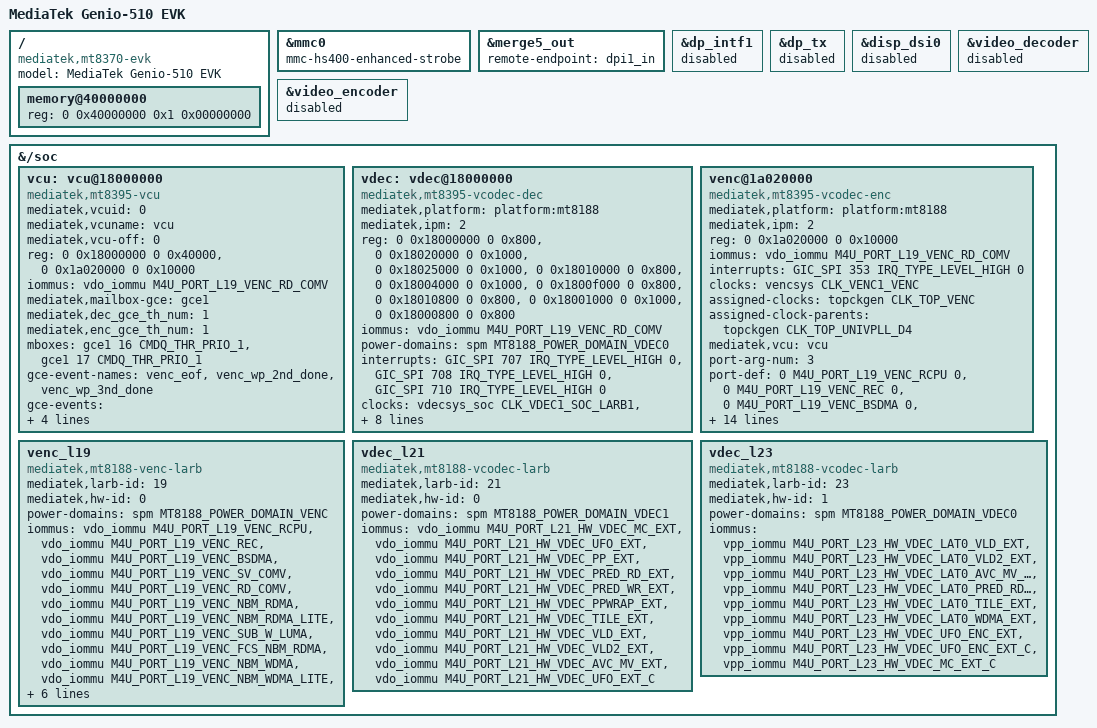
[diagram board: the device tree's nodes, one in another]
// SPDX-License-Identifier: (GPL-2.0 OR MIT)
/*
 * Copyright (c) 2025 Collabora Ltd.
 * Author: Louis-Alexis Eyraud <louisalexis.eyraud@collabora.com>
 */
/dts-v1/;

#include "mt8370.dtsi"
#include "mt8390-genio-common.dtsi"

/ {
	model = "MediaTek Genio-510 EVK";
	compatible = "mediatek,mt8370-evk", "mediatek,mt8370", "mediatek,mt8188";

	memory@40000000 {
		device_type = "memory";
		reg = <0 0x40000000 0x1 0x00000000>;
	};
};

&mmc0 {
	/*
	 * Run the eMMC at HS400 Enhanced Strobe. The fitted chip (Sandisk DG4064)
	 * supports it (EXT_CSD STROBE_SUPPORT[184]=0x01, verified). ES is
	 * self-aligning: the device drives the data strobe with the data, so the
	 * host skips the plain-HS400 DS-delay eye search
	 * (msdc_execute_hs400_tuning). That search is marginal on this board with
	 * the genio-common hs400-ds-delay-only config -- it intermittently fails
	 * cold with "Failed to get DLY1 delay" -> "error -5 whilst initialising
	 * MMC card". ES avoids it entirely (matches our u-boot, which runs ES, and
	 * the mt8188-geralt Chromebook). Genio-510-specific override -- not in the
	 * shared mt8390-genio-common.dtsi (genio-700/1200 use that too, untested).
	 */
	mmc-hs400-enhanced-strobe;
};

/*
 * Genio-510 uses HDMI, not DisplayPort. The shared mt8390-genio-common.dtsi
 * defines merge5_out -> dpi1_in (HDMI) but then redefines it -> dp_intf1_in
 * (DisplayPort) later in the same file, which wins by include order and leaves
 * the HDMI pipeline (vdosys1 -> ethdr0 -> merge5 -> dpi1 -> hdmi) with no
 * scanout. Re-point merge5_out at dpi1 here (board dts, included last).
 */
&merge5_out {
	remote-endpoint = <&dpi1_in>;
};

/*
 * Genio-510 has no DisplayPort output -- only HDMI. mt8390-genio-common.dtsi
 * enables dp_intf1 + dp_tx and wires them into the vdosys1 of-graph (for the
 * MT8390 EVK's USB-C DP-altmode). dp_intf1's mediatek-dpi probe defers forever
 * ("Failed to get bridge" -- dp_tx provides no bridge on this board), and because
 * mtk_drm_of_ddp_path_build walks the of-graph, the never-binding dp_intf1 is a
 * required component of the vdosys1 DRM master, which therefore never completes
 * component_master_bind -> no HDMI CRTC -> no mediatek KMS card (modetest sees
 * only panfrost: "not a KMS device"). Re-pointing merge5_out -> dpi1 (above) is
 * necessary but not sufficient; we must also remove dp_intf1/dp_tx from the graph.
 * Disable both so the vdosys1 master binds with the HDMI path only.
 */
&dp_intf1 {
	status = "disabled";
};

&dp_tx {
	status = "disabled";
};

/*
 * Genio-510 is HDMI-only with no physical MIPI-DSI panel. mt8390-genio-common.dtsi
 * enables &disp_dsi0 + a startek,kd070fhfid078 panel for the MT8390 EVK. On the 510
 * the vdosys0 DRM master (the PRIMARY that calls drm_dev_register for the single
 * shared mtk drm_device) never completes -- its dsi/panel component never registers
 * (device_component: mediatek-drm.5.auto "not bound", one component "not
 * registered") -- so NO mediatek KMS card appears even though the vdosys1/HDMI
 * master is bound. Disable disp_dsi0 so vdosys0 drops out and HDMI owns the device.
 */
&disp_dsi0 {
	status = "disabled";
};

/*
 * MT8188/MT8370 vendor VCU codec path (vpud + /dev/vcu).
 *
 * The mainline in-tree mtk-vcodec driver drives this silicon through the geralt
 * SCP, which decodes to empty pixels on this die (the VCU/VCP-vs-SCP coprocessor
 * wall, audit 2026-06-24). MediaTek's OFFICIAL Genio codec stack instead drives
 * the on-die VDEC/VENC from the userspace `vpud` daemon + `libvpud_vcodec.so` via
 * a /dev/vcu char device -- exactly the model already MERGED for MT8365 (Genio
 * 350). No coprocessor firmware is involved (vcu_load_firmware is a no-op).
 *
 * So disable the mainline SCP-path codec nodes on this board and bring up the
 * out-of-tree VCU stack (CONFIG_VIDEO_MEDIATEK_VCODEC_MT8395), whose driver binds
 * the mediatek,mt8395-* compatibles -- disjoint from the mainline mt8188-* ones,
 * so the two stacks never both claim a node. DT transcribed from MediaTek's Rity
 * BSP overlay recipes-kernel/dtbo/v6/mt8370/video.dts, with the iommu labels
 * mapped to our tree (iommu_vdo->vdo_iommu, iommu_vpp->vpp_iommu).
 */
&video_decoder {
	status = "disabled";
};

&video_encoder {
	status = "disabled";
};

&{/soc} {
	vcu: vcu@18000000 {
		compatible = "mediatek,mt8395-vcu";
		mediatek,vcuid = <0>;
		mediatek,vcuname = "vcu";
		mediatek,vcu-off = <0>;
		reg = <0 0x18000000 0 0x40000>,		/* VDEC_BASE */
		      <0 0x1a020000 0 0x10000>;		/* VENC_BASE */

		iommus = <&vdo_iommu M4U_PORT_L19_VENC_RD_COMV>;

		mediatek,mailbox-gce = <&gce1>;
		mediatek,dec_gce_th_num = <1>;
		mediatek,enc_gce_th_num = <1>;

		mboxes = <&gce1 16 CMDQ_THR_PRIO_1>,
			 <&gce1 17 CMDQ_THR_PRIO_1>;

		gce-event-names = "venc_eof",
				  "venc_wp_2nd_done",
				  "venc_wp_3nd_done";

		gce-events = <CMDQ_EVENT_VENC_TOP_VENC_FRAME_DONE>,
			     <CMDQ_EVENT_VENC_TOP_WP_2ND_STAGE_DONE>,
			     <CMDQ_EVENT_VENC_TOP_WP_3RD_STAGE_DONE>;

		/* GCE_GPR_R10 / GCE_GPR_R11 (gce/mt8195-gce.h: 0xa / 0xb) */
		gce-gpr = <0xa>, <0xb>;
	};

	vdec: vdec@18000000 {
		compatible = "mediatek,mt8395-vcodec-dec";
		mediatek,platform = "platform:mt8188";
		mediatek,ipm = <2>;
		reg = <0 0x18000000 0 0x800>,		/* VDEC_BASE */
		      <0 0x18020000 0 0x1000>,		/* VDEC_VLD */
		      <0 0x18025000 0 0x1000>,		/* VDEC_MISC */
		      <0 0x18010000 0 0x800>,		/* VDEC_LAT_MISC */
		      <0 0x18004000 0 0x1000>,		/* VDEC_RACING_CTRL */
		      <0 0x1800f000 0 0x800>,		/* VDEC_SOC_GCON */
		      <0 0x18010800 0 0x800>,		/* VDEC_LAT_WDMA */
		      <0 0x18001000 0 0x1000>,		/* VDEC_LAT_TOP */
		      <0 0x18000800 0 0x800>;		/* VDEC_UFO_ENC */
		reg-names = "VDEC_BASE",
			    "VDEC_VLD",
			    "VDEC_MISC",
			    "VDEC_LAT_MISC",
			    "VDEC_RACING_CTRL",
			    "VDEC_SOC_GCON",
			    "VDEC_LAT_WDMA",
			    "VDEC_LAT_TOP",
			    "VDEC_UFO_ENC";

		iommus = <&vdo_iommu M4U_PORT_L19_VENC_RD_COMV>;
		power-domains = <&spm MT8188_POWER_DOMAIN_VDEC0>;	/* SOC */
		interrupts = <GIC_SPI 707 IRQ_TYPE_LEVEL_HIGH 0>,
			     <GIC_SPI 708 IRQ_TYPE_LEVEL_HIGH 0>,
			     <GIC_SPI 710 IRQ_TYPE_LEVEL_HIGH 0>;

		clocks = <&vdecsys_soc CLK_VDEC1_SOC_LARB1>,
			 <&vdecsys_soc CLK_VDEC1_SOC_LAT>,
			 <&vdecsys_soc CLK_VDEC1_SOC_VDEC>,
			 <&vdecsys CLK_VDEC2_LARB1>,
			 <&vdecsys CLK_VDEC2_VDEC>;
		clock-names = "SOC_MT_CG_LARB1",
			      "LAT_MT_CG_VDEC",
			      "SOC_MT_CG_VDEC",
			      "CORE_MT_CG_LARB1",
			      "CORE_MT_CG_VDEC";

		assigned-clocks = <&topckgen CLK_TOP_VDEC>;
		assigned-clock-parents = <&apmixedsys CLK_APMIXED_TVDPLL2>;
		mediatek,vcu = <&vcu>;
	};

	venc@1a020000 {
		compatible = "mediatek,mt8395-vcodec-enc";
		mediatek,platform = "platform:mt8188";
		mediatek,ipm = <2>;
		reg = <0 0x1a020000 0 0x10000>;		/* VENC_C0 */
		reg-names = "VENC_SYS";
		iommus = <&vdo_iommu M4U_PORT_L19_VENC_RD_COMV>;
		interrupts = <GIC_SPI 353 IRQ_TYPE_LEVEL_HIGH 0>;
		clocks = <&vencsys CLK_VENC1_VENC>;
		clock-names = "MT_CG_VENC0";
		assigned-clocks = <&topckgen CLK_TOP_VENC>;
		assigned-clock-parents = <&topckgen CLK_TOP_UNIVPLL_D4>;
		mediatek,vcu = <&vcu>;
		port-arg-num = <3>;
		port-def = <0 M4U_PORT_L19_VENC_RCPU 0>,
			   <0 M4U_PORT_L19_VENC_REC 0>,
			   <0 M4U_PORT_L19_VENC_BSDMA 0>,
			   <0 M4U_PORT_L19_VENC_SV_COMV 0>,
			   <0 M4U_PORT_L19_VENC_RD_COMV 0>,
			   <0 M4U_PORT_L19_VENC_NBM_RDMA 1>,
			   <0 M4U_PORT_L19_VENC_NBM_RDMA_LITE 1>,
			   <0 M4U_PORT_L19_VENC_SUB_W_LUMA 0>,
			   <0 M4U_PORT_L19_VENC_FCS_NBM_RDMA 1>,
			   <0 M4U_PORT_L19_VENC_NBM_WDMA 1>,
			   <0 M4U_PORT_L19_VENC_NBM_WDMA_LITE 1>,
			   <0 M4U_PORT_L19_VENC_FCS_NBM_WDMA 1>,
			   <0 M4U_PORT_L19_VENC_CUR_LUMA 0>,
			   <0 M4U_PORT_L19_VENC_CUR_CHROMA 0>,
			   <0 M4U_PORT_L19_VENC_REF_LUMA 0>,
			   <0 M4U_PORT_L19_VENC_REF_CHROMA 0>,
			   <0 M4U_PORT_L19_VENC_SUB_R_LUMA 0>;
	};

	venc_l19 {
		compatible = "mediatek,mt8188-venc-larb";
		mediatek,larb-id = <19>;
		mediatek,hw-id = <0>;
		power-domains = <&spm MT8188_POWER_DOMAIN_VENC>;
		iommus = <&vdo_iommu M4U_PORT_L19_VENC_RCPU>,
			 <&vdo_iommu M4U_PORT_L19_VENC_REC>,
			 <&vdo_iommu M4U_PORT_L19_VENC_BSDMA>,
			 <&vdo_iommu M4U_PORT_L19_VENC_SV_COMV>,
			 <&vdo_iommu M4U_PORT_L19_VENC_RD_COMV>,
			 <&vdo_iommu M4U_PORT_L19_VENC_NBM_RDMA>,
			 <&vdo_iommu M4U_PORT_L19_VENC_NBM_RDMA_LITE>,
			 <&vdo_iommu M4U_PORT_L19_VENC_SUB_W_LUMA>,
			 <&vdo_iommu M4U_PORT_L19_VENC_FCS_NBM_RDMA>,
			 <&vdo_iommu M4U_PORT_L19_VENC_NBM_WDMA>,
			 <&vdo_iommu M4U_PORT_L19_VENC_NBM_WDMA_LITE>,
			 <&vdo_iommu M4U_PORT_L19_VENC_FCS_NBM_WDMA>,
			 <&vdo_iommu M4U_PORT_L19_VENC_CUR_LUMA>,
			 <&vdo_iommu M4U_PORT_L19_VENC_CUR_CHROMA>,
			 <&vdo_iommu M4U_PORT_L19_VENC_REF_LUMA>,
			 <&vdo_iommu M4U_PORT_L19_VENC_REF_CHROMA>,
			 <&vdo_iommu M4U_PORT_L19_VENC_SUB_R_LUMA>;
	};

	vdec_l21 {
		compatible = "mediatek,mt8188-vcodec-larb";
		mediatek,larb-id = <21>;
		mediatek,hw-id = <0>;
		power-domains = <&spm MT8188_POWER_DOMAIN_VDEC1>;	/* core0 */
		iommus = <&vdo_iommu M4U_PORT_L21_HW_VDEC_MC_EXT>,
			 <&vdo_iommu M4U_PORT_L21_HW_VDEC_UFO_EXT>,
			 <&vdo_iommu M4U_PORT_L21_HW_VDEC_PP_EXT>,
			 <&vdo_iommu M4U_PORT_L21_HW_VDEC_PRED_RD_EXT>,
			 <&vdo_iommu M4U_PORT_L21_HW_VDEC_PRED_WR_EXT>,
			 <&vdo_iommu M4U_PORT_L21_HW_VDEC_PPWRAP_EXT>,
			 <&vdo_iommu M4U_PORT_L21_HW_VDEC_TILE_EXT>,
			 <&vdo_iommu M4U_PORT_L21_HW_VDEC_VLD_EXT>,
			 <&vdo_iommu M4U_PORT_L21_HW_VDEC_VLD2_EXT>,
			 <&vdo_iommu M4U_PORT_L21_HW_VDEC_AVC_MV_EXT>,
			 <&vdo_iommu M4U_PORT_L21_HW_VDEC_UFO_EXT_C>;
	};

	vdec_l23 {
		compatible = "mediatek,mt8188-vcodec-larb";
		mediatek,larb-id = <23>;
		mediatek,hw-id = <1>;
		power-domains = <&spm MT8188_POWER_DOMAIN_VDEC0>;	/* soc */
		iommus = <&vpp_iommu M4U_PORT_L23_HW_VDEC_LAT0_VLD_EXT>,
			 <&vpp_iommu M4U_PORT_L23_HW_VDEC_LAT0_VLD2_EXT>,
			 <&vpp_iommu M4U_PORT_L23_HW_VDEC_LAT0_AVC_MV_EXT>,
			 <&vpp_iommu M4U_PORT_L23_HW_VDEC_LAT0_PRED_RD_EXT>,
			 <&vpp_iommu M4U_PORT_L23_HW_VDEC_LAT0_TILE_EXT>,
			 <&vpp_iommu M4U_PORT_L23_HW_VDEC_LAT0_WDMA_EXT>,
			 <&vpp_iommu M4U_PORT_L23_HW_VDEC_UFO_ENC_EXT>,
			 <&vpp_iommu M4U_PORT_L23_HW_VDEC_UFO_ENC_EXT_C>,
			 <&vpp_iommu M4U_PORT_L23_HW_VDEC_MC_EXT_C>;
	};
};
